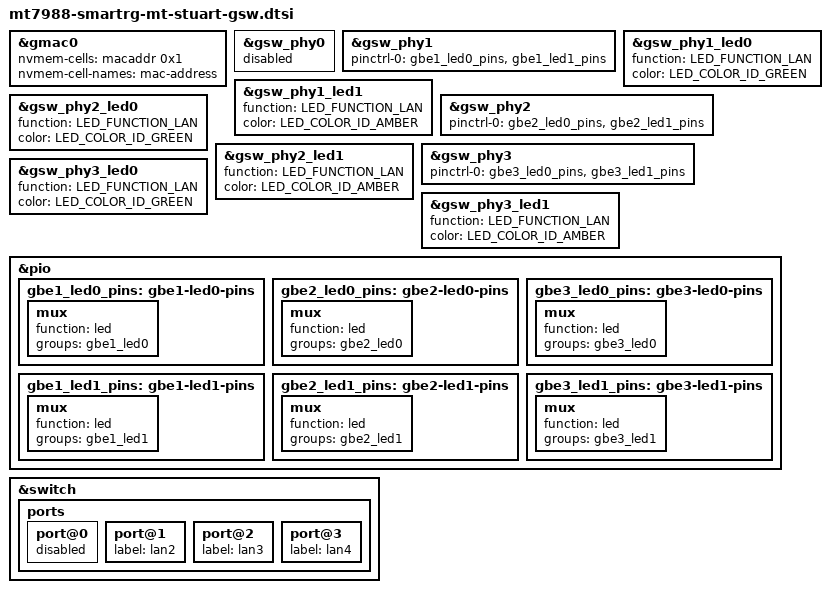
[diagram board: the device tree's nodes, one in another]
// SPDX-License-Identifier: (GPL-2.0 OR MIT)
/*
 * Copyright (C) 2026 SmartRG Inc.
 * Author: Chad Monroe <chad.monroe@smartrg.com>
 *
 * MT7988 built-in gigabit switch as lan2..lan4 with the per-port
 * PHY LEDs, shared by the Mt. Stuart designs that expose the gsw
 * ports.
 */

&gmac0 {
	nvmem-cells = <&macaddr 0x1>;
	nvmem-cell-names = "mac-address";

	status = "okay";
};

&gsw_phy0 {
	status = "disabled";
};

&gsw_phy1 {
	pinctrl-names = "gbe-led";
	pinctrl-0 = <&gbe1_led0_pins>, <&gbe1_led1_pins>;
};

&gsw_phy1_led0 {
	status = "okay";
	function = LED_FUNCTION_LAN;
	color = <LED_COLOR_ID_GREEN>;
};

&gsw_phy1_led1 {
	status = "okay";
	function = LED_FUNCTION_LAN;
	color = <LED_COLOR_ID_AMBER>;
};

&gsw_phy2 {
	pinctrl-names = "gbe-led";
	pinctrl-0 = <&gbe2_led0_pins>, <&gbe2_led1_pins>;
};

&gsw_phy2_led0 {
	status = "okay";
	function = LED_FUNCTION_LAN;
	color = <LED_COLOR_ID_GREEN>;
};

&gsw_phy2_led1 {
	status = "okay";
	function = LED_FUNCTION_LAN;
	color = <LED_COLOR_ID_AMBER>;
};

&gsw_phy3 {
	pinctrl-names = "gbe-led";
	pinctrl-0 = <&gbe3_led0_pins>, <&gbe3_led1_pins>;
};

&gsw_phy3_led0 {
	status = "okay";
	function = LED_FUNCTION_LAN;
	color = <LED_COLOR_ID_GREEN>;
};

&gsw_phy3_led1 {
	status = "okay";
	function = LED_FUNCTION_LAN;
	color = <LED_COLOR_ID_AMBER>;
};

&pio {
	gbe1_led0_pins: gbe1-led0-pins {
		mux {
			function = "led";
			groups = "gbe1_led0";
		};
	};

	gbe2_led0_pins: gbe2-led0-pins {
		mux {
			function = "led";
			groups = "gbe2_led0";
		};
	};

	gbe3_led0_pins: gbe3-led0-pins {
		mux {
			function = "led";
			groups = "gbe3_led0";
		};
	};

	gbe1_led1_pins: gbe1-led1-pins {
		mux {
			function = "led";
			groups = "gbe1_led1";
		};
	};

	gbe2_led1_pins: gbe2-led1-pins {
		mux {
			function = "led";
			groups = "gbe2_led1";
		};
	};

	gbe3_led1_pins: gbe3-led1-pins {
		mux {
			function = "led";
			groups = "gbe3_led1";
		};
	};
};

&switch {
	status = "okay";

	ports {
		port@0 {
			status = "disabled";
		};

		port@1 {
			label = "lan2";
		};

		port@2 {
			label = "lan3";
		};

		port@3 {
			label = "lan4";
		};
	};
};
